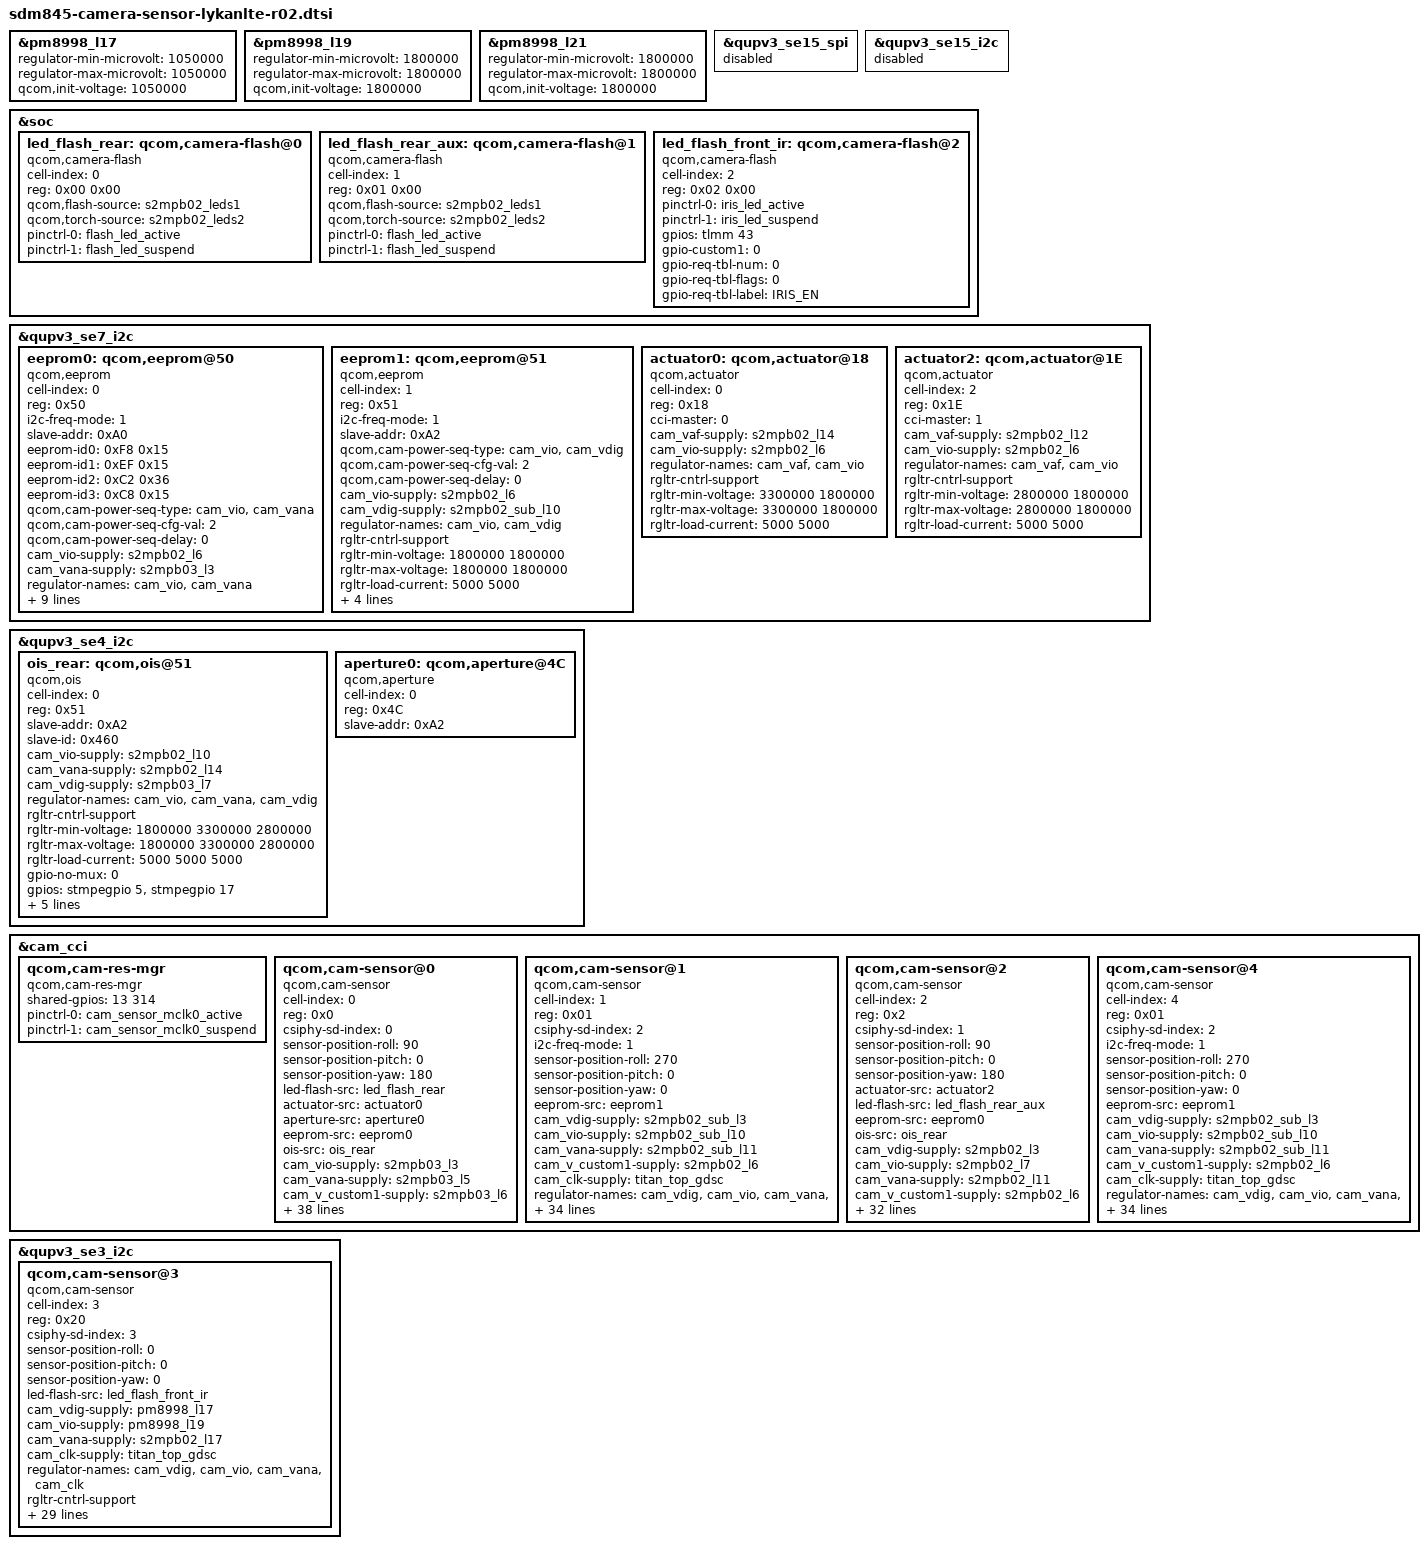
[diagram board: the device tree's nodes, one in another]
/*
 * Copyright (c) 2016-2017, The Linux Foundation. All rights reserved.
 *
 * This program is free software; you can redistribute it and/or modify
 * it under the terms of the GNU General Public License version 2 and
 * only version 2 as published by the Free Software Foundation.
 *
 * This program is distributed in the hope that it will be useful,
 * but WITHOUT ANY WARRANTY; without even the implied warranty of
 * MERCHANTABILITY or FITNESS FOR A PARTICULAR PURPOSE.  See the
 * GNU General Public License for more details.
 */

&pm8998_l17 {
	regulator-min-microvolt = <1050000>;
	regulator-max-microvolt = <1050000>;
	qcom,init-voltage = <1050000>;
};

&pm8998_l19 {
	regulator-min-microvolt = <1800000>;
	regulator-max-microvolt = <1800000>;
	qcom,init-voltage = <1800000>;
};

&pm8998_l21 {
	regulator-min-microvolt = <1800000>;
	regulator-max-microvolt = <1800000>;
	qcom,init-voltage = <1800000>;
};

&qupv3_se15_spi {
	status = "disabled";
};
  
&qupv3_se15_i2c {
	status = "disabled";
};

&soc {
	led_flash_rear: qcom,camera-flash@0 {
		cell-index = <0>;
		reg = <0x00 0x00>;
		compatible = "qcom,camera-flash";
		qcom,flash-source = <&s2mpb02_leds1>;
		qcom,torch-source = <&s2mpb02_leds2>;
		pinctrl-names = "cam_default", "cam_suspend";
		pinctrl-0 = <&flash_led_active>;
		pinctrl-1 = <&flash_led_suspend>;
		status = "ok";
	};

	led_flash_rear_aux: qcom,camera-flash@1 {
		cell-index = <1>;
		reg = <0x01 0x00>;
		compatible = "qcom,camera-flash";
		qcom,flash-source = <&s2mpb02_leds1>;
		qcom,torch-source = <&s2mpb02_leds2>;
		pinctrl-names = "cam_default", "cam_suspend";
		pinctrl-0 = <&flash_led_active>;
		pinctrl-1 = <&flash_led_suspend>;
		status = "ok";
	};

	led_flash_front_ir: qcom,camera-flash@2 {
		cell-index = <2>;
		reg = <0x02 0x00>;
		compatible = "qcom,camera-flash";
		pinctrl-names = "cam_default", "cam_suspend";
		pinctrl-0 = <&iris_led_active>;
		pinctrl-1 = <&iris_led_suspend>;
		gpios = <&tlmm 43 0>; /* IRIS_EN */
		gpio-custom1 = <0>;
		gpio-req-tbl-num = <0>;
		gpio-req-tbl-flags = <0>;
		gpio-req-tbl-label = "IRIS_EN";
		status = "ok";
	};
};

&qupv3_se7_i2c {

	status = "ok";
	eeprom0: qcom,eeprom@50 {
		cell-index = <0>;
		reg = <0x50>;
		compatible = "qcom,eeprom";

		i2c-freq-mode = <1>;
		slave-addr = <0xA0>;

		eeprom-id0 = <0xF8 0x15>;
		eeprom-id1 = <0xEF 0x15>;
		eeprom-id2 = <0xC2 0x36>;
		eeprom-id3 = <0xC8 0x15>;

		qcom,cam-power-seq-type = "cam_vio","cam_vana";
		qcom,cam-power-seq-cfg-val = <2>;
		qcom,cam-power-seq-delay = <0>;

		cam_vio-supply = <&s2mpb02_l6>; /* VDD_VTCAM_IO_1P8 */
		cam_vana-supply = <&s2mpb03_l3>;
		regulator-names = "cam_vio" , "cam_vana";
		rgltr-cntrl-support;
		rgltr-min-voltage = <1800000 1800000>;
		rgltr-max-voltage = <1800000 1800000>;
		rgltr-load-current = <5000 5000>;
		gpio-no-mux = <1>;
		sensor-position = <0>;
		sensor-mode = <0>;
		cci-master = <1>;
		multimodule-support;

		status = "ok";
	};

	eeprom1: qcom,eeprom@51 {
		cell-index = <1>;
		reg = <0x51>;
		compatible = "qcom,eeprom";
		i2c-freq-mode = <1>;
		slave-addr = <0xA2>;

		qcom,cam-power-seq-type = "cam_vio", "cam_vdig";
		qcom,cam-power-seq-cfg-val = <2>;
		qcom,cam-power-seq-delay = <0>;

		cam_vio-supply = <&s2mpb02_l6>; /* VDD_VTCAM_IO_1P8 */
		cam_vdig-supply = <&s2mpb02_sub_l10>; /* VDD_VTCAM_IO_1P8 */
		regulator-names = "cam_vio", "cam_vdig";
		rgltr-cntrl-support;
		rgltr-min-voltage = <1800000 1800000>;
		rgltr-max-voltage = <1800000 1800000>;
		rgltr-load-current = <5000 5000>;
		gpio-no-mux = <1>;
		sensor-position = <1>;
		sensor-mode = <0>;
		cci-master = <1>;
		status = "ok";
	};
	
	actuator0: qcom,actuator@18 { /* Wide */
		cell-index = <0>;
		reg = <0x18>;
		compatible = "qcom,actuator";
		cci-master = <0>;
		cam_vaf-supply = <&s2mpb02_l14>;
		cam_vio-supply = <&s2mpb02_l6>;   /* VDD_VTCAM_IO_1P8 */
		regulator-names = "cam_vaf", "cam_vio";
		rgltr-cntrl-support;
		rgltr-min-voltage = <3300000 1800000>;
		rgltr-max-voltage = <3300000 1800000>;
		rgltr-load-current = <5000 5000>;
		status = "ok";
	};
	
	actuator2: qcom,actuator@1E { /* Tele */
		cell-index = <2>;
		reg = <0x1E>;
		compatible = "qcom,actuator";
		cci-master = <1>;
		cam_vaf-supply = <&s2mpb02_l12>;
		cam_vio-supply = <&s2mpb02_l6>;   /* VDD_VTCAM_IO_1P8 */
		regulator-names = "cam_vaf", "cam_vio";
		rgltr-cntrl-support;
		rgltr-min-voltage = <2800000 1800000>;
		rgltr-max-voltage = <2800000 1800000>;
		rgltr-load-current = <5000 5000>;
		status = "ok";
	};
};

&qupv3_se4_i2c {
	status = "ok";
	
	ois_rear: qcom,ois@51  {
		compatible = "qcom,ois";
		cell-index = <0>;
		reg = <0x51>;
		slave-addr = <0xA2>;
		slave-id = <0x460>;
		//cci-master = <0>;
		cam_vio-supply = <&s2mpb02_l10>; /* VDD_OIS_1P8 */
		cam_vana-supply = <&s2mpb02_l14>;
		cam_vdig-supply = <&s2mpb03_l7>; /* VDD_OIS_VM_2P8 */
		regulator-names = "cam_vio", "cam_vana", "cam_vdig";
		rgltr-cntrl-support;
		rgltr-min-voltage = <1800000 3300000 2800000>;
		rgltr-max-voltage = <1800000 3300000 2800000>;
		rgltr-load-current = <5000 5000 5000>;
		gpio-no-mux = <0>;
		gpios = <&stmpegpio 5 0>, // RESET
			<&stmpegpio 17 0>; // BOOT0
		gpio-reset = <0>;
		gpio-custom1 = <1>;
		gpio-req-tbl-num = <0 1>;
		gpio-req-tbl-flags = <0 0>;
		gpio-req-tbl-label = "MCU_RESET0", "MCU_BOOT0";
		status = "ok";
	};

	aperture0: qcom,aperture@4C {
		cell-index = <0>;
		reg = <0x4C>;
		compatible = "qcom,aperture";
		slave-addr = <0xA2>;
		status = "ok";
	};	
};

&cam_cci {
	qcom,cam-res-mgr {
		compatible = "qcom,cam-res-mgr";
		shared-gpios = <13 314>;
		pinctrl-names = "cam_res_mgr_default", "cam_res_mgr_suspend";
		status = "ok";
		pinctrl-0 = <&cam_sensor_mclk0_active>;
		pinctrl-1 = <&cam_sensor_mclk0_suspend>;
	};

	qcom,cam-sensor@0 {
		cell-index = <0>;
		compatible = "qcom,cam-sensor";
		reg = <0x0>;
		csiphy-sd-index = <0>;
		sensor-position-roll = <90>;
		sensor-position-pitch = <0>;
		sensor-position-yaw = <180>;
		led-flash-src = <&led_flash_rear>;
		actuator-src = <&actuator0>;
		aperture-src = <&aperture0>;
		eeprom-src = <&eeprom0>;
		ois-src = <&ois_rear>;
		//cam_vdig-supply = <&s2mpb02_l3>;  // FRS_DIGITAL_1P0 
		cam_vio-supply = <&s2mpb03_l3>;
		cam_vana-supply = <&s2mpb03_l5>;
		cam_v_custom1-supply = <&s2mpb03_l6>;
		cam_v_custom2-supply = <&s2mpb03_l2>;
		cam_v_custom10-supply = <&s2mpb03_l4>; /* FRS_RET_1P1 */
		cam_clk-supply = <&titan_top_gdsc>;
		regulator-names = "cam_vio", "cam_vana", "cam_v_custom1", "cam_v_custom2", "cam_v_custom10", "cam_clk";
		rgltr-cntrl-support;
		rgltr-min-voltage = <1800000 3200000 2850000 1100000 1100000 0>;
		rgltr-max-voltage = <1800000 3200000 2850000 1100000 1100000 0>;
		rgltr-load-current = <200000 50000 200000 5000 5000 0>;
		gpio-no-mux = <0>;
		use-shared-clk;
		pinctrl-names = "cam_default", "cam_suspend";
		pinctrl-0 = <&cam_sensor_rear_active>;
		pinctrl-1 = <&cam_sensor_rear_suspend>;
		gpios = <&tlmm 13 0>, /* MCLK */
			<&tlmm 25 0>; /* RESET */
		gpio-reset = <1>;
		gpio-req-tbl-num = <0 1>;
		gpio-req-tbl-flags = <1 0>;
		gpio-req-tbl-label = "CAMIF_MCLK0",
					"CAM_RESET0";
		sensor-mode = <0>;
		cci-master = <0>;
		status = "ok";
		clocks = <&clock_camcc CAM_CC_MCLK0_CLK>;
		clock-names = "cam_clk";
		clock-cntl-level = "turbo";
		clock-rates = <24000000>;

		cam,isp = <0>;                  // 0 : INT , 1 : EXT , 2 : SOC
		cam,cal_memory = <2>;           // 0 : N , 1 : FROM , 2 : EEPROM , 3 : OTP
		cam,read_version = <1>;         // 0 : SYSFS , 1 : CAMON
		cam,core_voltage = <1>;         // 0 : N , 1 : Y
		cam,upgrade = <2>;              // 0 : N , 1 : SYSFS , 2 : CAMON
		cam,fw_write = <3>;             // 0 : N , 1 : OS , 2 : SD , 3 : ALL
		cam,fw_dump = <1>;              // 0 : N , 1 : Y
		cam,companion_chip = <0>;       // 0 : N , 1 : Y
		cam,ois = <1>;                  // 0 : N , 1 : Y
		cam,dual_open = <0>;            // 0 : N , 1 : Y
		cam,valid = <1>;                // 0 : N , 1 : Y
	};

	qcom,cam-sensor@1 {
		cell-index = <1>;
		compatible = "qcom,cam-sensor";
		reg = <0x01>;
		csiphy-sd-index = <2>;
		i2c-freq-mode = <1>;
		sensor-position-roll = <270>;
		sensor-position-pitch = <0>;
		sensor-position-yaw = <0>;
		eeprom-src = <&eeprom1>;
		cam_vdig-supply = <&s2mpb02_sub_l3>;
		cam_vio-supply = <&s2mpb02_sub_l10>;
		cam_vana-supply = <&s2mpb02_sub_l11>;
		cam_v_custom1-supply = <&s2mpb02_l6>;
		cam_clk-supply = <&titan_top_gdsc>;
		regulator-names = "cam_vdig", "cam_vio", "cam_vana", "cam_v_custom1", "cam_clk";
		rgltr-cntrl-support;
		rgltr-min-voltage = <1200000 1800000 2800000 1800000 0>;
		rgltr-max-voltage = <1200000 1800000 2800000 1800000 0>;
		rgltr-load-current = <200000 200000 5000 200000 0>;
		gpio-no-mux = <0>;
		pinctrl-names = "cam_default", "cam_suspend";
		pinctrl-0 = <&cam_sensor_mclk2_active
				 &cam_sensor_front_active>;
		pinctrl-1 = <&cam_sensor_mclk2_suspend
				 &cam_sensor_front_suspend>;
		gpios = <&tlmm 15 0>,
			<&tlmm 12 0>;
		gpio-reset = <1>;
		gpio-req-tbl-num = <0 1>;
		gpio-req-tbl-flags = <1 0>;
		gpio-req-tbl-label = "CAMIF_MCLK2",
					"CAM_RESET2";
		sensor-mode = <0>;
		cci-master = <1>;
		status = "ok";
		clocks = <&clock_camcc CAM_CC_MCLK2_CLK>;
		clock-names = "cam_clk";
		clock-cntl-level = "turbo";
		clock-rates = <24000000>;

		cam,isp = <0>;                  // 0 : INT , 1 : EXT , 2 : SOC
		cam,cal_memory = <2>;           // 0 : N , 1 : FROM , 2 : EEPROM , 3 : OTP
		cam,read_version = <0>;         // 0 : SYSFS , 1 : CAMON
		cam,core_voltage = <0>;         // 0 : N , 1 : Y
		cam,upgrade = <0>;              // 0 : N , 1 : SYSFS , 2 : CAMON
		cam,fw_write = <0>;             // 0 : N , 1 : OS , 2 : SD , 3 : ALL
		cam,fw_dump = <0>;              // 0 : N , 1 : Y
		cam,companion_chip = <0>;       // 0 : N , 1 : Y
		cam,ois = <0>;                  // 0 : N , 1 : Y
		cam,dual_open = <0>;            // 0 : N , 1 : Y
		cam,valid = <1>;                // 0 : N , 1 : Y
	};

	qcom,cam-sensor@2 {
		cell-index = <2>;
		compatible = "qcom,cam-sensor";
		reg = <0x2>;
		csiphy-sd-index = <1>;
		sensor-position-roll = <90>;
		sensor-position-pitch = <0>;
		sensor-position-yaw = <180>;
		actuator-src = <&actuator2>;
		led-flash-src = <&led_flash_rear_aux>;
		eeprom-src = <&eeprom0>;
		ois-src = <&ois_rear>;
		cam_vdig-supply = <&s2mpb02_l3>; //<&s2mpb02_l3>;
		cam_vio-supply = <&s2mpb02_l7>;
		cam_vana-supply = <&s2mpb02_l11>;
		cam_v_custom1-supply = <&s2mpb02_l6>; /* VDD_VTCAM_IO_1P8 */
		cam_clk-supply = <&titan_top_gdsc>;
		regulator-names = "cam_vdig", "cam_vio", "cam_vana", "cam_v_custom1", "cam_clk";
		rgltr-cntrl-support;
		rgltr-min-voltage = <1000000 1800000 2800000 1800000 0>;
		rgltr-max-voltage = <1000000 1800000 2800000 1800000 0>;
		rgltr-load-current = <200000 200000 50000 5000 0>;
		gpio-no-mux = <0>;
		use-shared-clk;
		gpios = <&tlmm 13 0>, /* MCLK */
			<&tlmm 2 0>; /* RESET */
		gpio-reset = <1>;
		gpio-req-tbl-num = <0 1>;
		gpio-req-tbl-flags = <1 0>;
		gpio-req-tbl-label = "CAMIF_MCLK0",
					"CAM_SUB_RESET";
		sensor-mode = <0>;
		cci-master = <1>;
		status = "ok";
		clocks = <&clock_camcc CAM_CC_MCLK0_CLK>;
		clock-names = "cam_clk";
		clock-cntl-level = "turbo";
		clock-rates = <24000000>;

		cam,isp = <0>;                  // 0 : INT , 1 : EXT , 2 : SOC
		cam,cal_memory = <2>;           // 0 : N , 1 : FROM , 2 : EEPROM , 3 : OTP
		cam,read_version = <0>;         // 0 : SYSFS , 1 : CAMON
		cam,core_voltage = <0>;         // 0 : N , 1 : Y
		cam,upgrade = <0>;              // 0 : N , 1 : SYSFS , 2 : CAMON
		cam,fw_write = <0>;             // 0 : N , 1 : OS , 2 : SD , 3 : ALL
		cam,fw_dump = <0>;              // 0 : N , 1 : Y
		cam,companion_chip = <0>;       // 0 : N , 1 : Y
		cam,ois = <1>;                  // 0 : N , 1 : Y
		cam,dual_open = <0>;            // 0 : N , 1 : Y
		cam,valid = <1>;                // 0 : N , 1 : Y
	};

	qcom,cam-sensor@4 {
		cell-index = <4>;
		compatible = "qcom,cam-sensor";
		reg = <0x01>;
		csiphy-sd-index = <2>;
		i2c-freq-mode = <1>;
		sensor-position-roll = <270>;
		sensor-position-pitch = <0>;
		sensor-position-yaw = <0>;
		eeprom-src = <&eeprom1>;
		cam_vdig-supply = <&s2mpb02_sub_l3>;
		cam_vio-supply = <&s2mpb02_sub_l10>;
		cam_vana-supply = <&s2mpb02_sub_l11>;
		cam_v_custom1-supply = <&s2mpb02_l6>;
		cam_clk-supply = <&titan_top_gdsc>;
		regulator-names = "cam_vdig", "cam_vio", "cam_vana", "cam_v_custom1", "cam_clk";
		rgltr-cntrl-support;
		rgltr-min-voltage = <1200000 1800000 2800000 1800000 0>;
		rgltr-max-voltage = <1200000 1800000 2800000 1800000 0>;
		rgltr-load-current = <200000 200000 5000 200000 0>;
		gpio-no-mux = <0>;
		pinctrl-names = "cam_default", "cam_suspend";
		pinctrl-0 = <&cam_sensor_mclk2_active
				 &cam_sensor_front_active>;
		pinctrl-1 = <&cam_sensor_mclk2_suspend
				 &cam_sensor_front_suspend>;
		gpios = <&tlmm 15 0>,
			<&tlmm 12 0>;
		gpio-reset = <1>;
		gpio-req-tbl-num = <0 1>;
		gpio-req-tbl-flags = <1 0>;
		gpio-req-tbl-label = "CAMIF_MCLK2",
					"CAM_RESET2";
		sensor-mode = <0>;
		cci-master = <1>;
		status = "ok";
		clocks = <&clock_camcc CAM_CC_MCLK2_CLK>;
		clock-names = "cam_clk";
		clock-cntl-level = "turbo";
		clock-rates = <24000000>;

		cam,isp = <0>;                  // 0 : INT , 1 : EXT , 2 : SOC
		cam,cal_memory = <2>;           // 0 : N , 1 : FROM , 2 : EEPROM , 3 : OTP
		cam,read_version = <0>;         // 0 : SYSFS , 1 : CAMON
		cam,core_voltage = <0>;         // 0 : N , 1 : Y
		cam,upgrade = <0>;              // 0 : N , 1 : SYSFS , 2 : CAMON
		cam,fw_write = <0>;             // 0 : N , 1 : OS , 2 : SD , 3 : ALL
		cam,fw_dump = <0>;              // 0 : N , 1 : Y
		cam,companion_chip = <0>;       // 0 : N , 1 : Y
		cam,ois = <0>;                  // 0 : N , 1 : Y
		cam,dual_open = <0>;            // 0 : N , 1 : Y
		cam,valid = <1>;                // 0 : N , 1 : Y
	};

};


&qupv3_se3_i2c {
	status = "ok";
	
	qcom,cam-sensor@3 {
		cell-index = <3>;
		compatible = "qcom,cam-sensor";
		reg = <0x20>;
		csiphy-sd-index = <3>;
		sensor-position-roll = <0>;
		sensor-position-pitch = <0>;
		sensor-position-yaw = <0>;

		led-flash-src = <&led_flash_front_ir>;
		cam_vdig-supply = <&pm8998_l17>;
		cam_vio-supply = <&pm8998_l19>;
		cam_vana-supply = <&s2mpb02_l17>;
		cam_clk-supply = <&titan_top_gdsc>;
		regulator-names = "cam_vdig", "cam_vio", "cam_vana", "cam_clk";
		rgltr-cntrl-support;
		rgltr-min-voltage = <1050000 1800000 2800000 0>;
		rgltr-max-voltage = <1050000 1800000 2800000 0>;
		rgltr-load-current = <200000 200000 5000 0>;
		gpio-no-mux = <0>;
		pinctrl-names = "cam_default", "cam_suspend";
		pinctrl-0 = <&cam_sensor_mclk3_active &cam_sensor_iris_active>;
		pinctrl-1 = <&cam_sensor_mclk3_suspend &cam_sensor_iris_suspend>;
		gpios = <&tlmm 16 0>, /* MCLK */
			<&tlmm 44 0>; /* RESET */
		gpio-reset = <1>;
		gpio-req-tbl-num = <0 1>;
		gpio-req-tbl-flags = <1 0>;
		gpio-req-tbl-label = "CAMIF_MCLK3",
					"CAM_RESET3";
		sensor-mode = <0>;
		cci-master = <1>;
		status = "ok";
		clocks = <&clock_camcc CAM_CC_MCLK3_CLK>;
		clock-names = "cam_clk";
		clock-cntl-level = "turbo";
		clock-rates = <24000000>;

		cam,isp = <2>;                  // 0 : INT , 1 : EXT , 2 : SOC
		cam,cal_memory = <0>;           // 0 : N , 1 : FROM , 2 : EEPROM , 3 : OTP
		cam,read_version = <0>;         // 0 : SYSFS , 1 : CAMON
		cam,core_voltage = <0>;         // 0 : N , 1 : Y
		cam,upgrade = <0>;              // 0 : N , 1 : SYSFS , 2 : CAMON
		cam,fw_write = <0>;             // 0 : N , 1 : OS , 2 : SD , 3 : ALL
		cam,fw_dump = <0>;              // 0 : N , 1 : Y
		cam,companion_chip = <0>;       // 0 : N , 1 : Y
		cam,ois = <0>;                  // 0 : N , 1 : Y
		cam,dual_open = <0>;            // 0 : N , 1 : Y
		cam,valid = <1>;                // 0 : N , 1 : Y
	};
};
